AUTOSAR XML (schema 00044)
package /E40_Platform_System_SystemPackage/Components
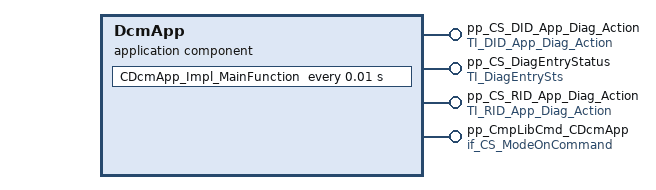
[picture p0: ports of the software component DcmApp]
  application sw component type DcmApp
    4 x provide port:
      pp_CS_DID_App_Diag_Action: server-com-spec{operation=DID_DiagAction, queue-length=1}, provided-interface=TI_DID_App_Diag_Action
      pp_CS_DiagEntryStatus: server-com-spec{operation=Diag_Entry_Status, queue-length=1}, provided-interface=TI_DiagEntrySts
      pp_CS_RID_App_Diag_Action: server-com-spec{operation=RID_DiagAction, queue-length=1}, provided-interface=TI_RID_App_Diag_Action
      pp_CmpLibCmd_CDcmApp: server-com-spec{operation=Impl_OnCommand, queue-length=1}, provided-interface=if_CS_ModeOnCommand
    behavior IB_DcmApp
      operation invoked event OIE_pp_CS_DID_App_Diag_Action_CDcmApp_DID_DiagActionTrigByDID_DiagAction: start-on-event=CDcmApp_DID_DiagAction, operation=pp_CS_DID_App_Diag_Action.DID_DiagAction
      operation invoked event OIE_pp_CS_DiagEntryStatus_CDcmApp_Diag_Entry_StatusTrigByDiag_Entry_Status: start-on-event=CDcmApp_Diag_Entry_Status, operation=pp_CS_DiagEntryStatus.Diag_Entry_Status
      timing event TECDcmApp_Impl_MainFunction: start-on-event=CDcmApp_Impl_MainFunction, period=0.01
      operation invoked event OIE_pp_CmpLibCmd_CDcmApp_CDcmApp_Impl_OnCommandTrigByImpl_OnCommand: start-on-event=CDcmApp_Impl_OnCommand, operation=pp_CmpLibCmd_CDcmApp.Impl_OnCommand
      operation invoked event OIE_pp_CS_RID_App_Diag_Action_CDcmApp_RID_DiagActionTrigByRID_DiagAction: start-on-event=CDcmApp_RID_DiagAction, operation=pp_CS_RID_App_Diag_Action.RID_DiagAction
      port-api-options:
        enable-take-address=false, indirect-api=false, port=pp_CS_DID_App_Diag_Action
        enable-take-address=false, indirect-api=false, port=pp_CS_DiagEntryStatus
        enable-take-address=false, indirect-api=false, port=pp_CS_RID_App_Diag_Action
        enable-take-address=false, indirect-api=false, port=pp_CmpLibCmd_CDcmApp
      5 x runnable, all with can-be-invoked-concurrently=true:
        CDcmApp_DID_DiagAction
        CDcmApp_Diag_Entry_Status
        CDcmApp_Impl_MainFunction
        CDcmApp_Impl_OnCommand
        CDcmApp_RID_DiagAction
  swc implementation IMPL_DcmApp: behavior=IB_DcmApp
